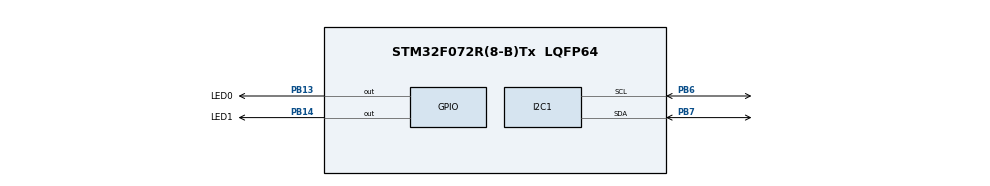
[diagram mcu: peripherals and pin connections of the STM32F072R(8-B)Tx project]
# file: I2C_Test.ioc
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Mcu.Family=STM32F0
Mcu.Name=STM32F072R(8-B)Tx
Mcu.Package=LQFP64
PB13.GPIO_Label=LED0
PB13.Signal=GPIO_Output
PB14.GPIO_Label=LED1
PB14.Signal=GPIO_Output
PB6.Mode=I2C
PB6.Signal=I2C1_SCL
PB7.Mode=I2C
PB7.Signal=I2C1_SDA
ProjectManager.HeapSize=0x200
ProjectManager.StackSize=0x400
ProjectManager.TargetToolchain=TrueSTUDIO
board=custom

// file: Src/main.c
/* USER CODE BEGIN Header */
/**
  ******************************************************************************
  * @file           : main.c
  * @brief          : Main program body
  ******************************************************************************
  * @attention
  *
  * <h2><center>&copy; Copyright (c) 2019 STMicroelectronics.
  * All rights reserved.</center></h2>
  *
  * This software component is licensed by ST under BSD 3-Clause license,
  * the "License"; You may not use this file except in compliance with the
  * License. You may obtain a copy of the License at:
  *                        opensource.org/licenses/BSD-3-Clause
  *
  ******************************************************************************
  */
/* USER CODE END Header */

#include "main.h"

/* USER CODE BEGIN Includes */
#include "pca9685.h"
#include "AFE.h"
/* USER CODE END Includes */

I2C_HandleTypeDef hi2c1;

void SystemClock_Config(void);
static void MX_GPIO_Init(void);
static void MX_I2C1_Init(void);

int main(void)
{

  /* MCU Configuration--------------------------------------------------------*/

  /* Reset of all peripherals, Initializes the Flash interface and the Systick. */
  HAL_Init();

  /* Configure the system clock */
  SystemClock_Config();

  /* Initialize all configured peripherals */
  MX_GPIO_Init();
  MX_I2C1_Init();
  /* USER CODE BEGIN 2 */

  pca_wake(&hi2c1);

  HAL_Delay(1000);
  pca_init(&hi2c1);
  pca_off(&hi2c1);
  HAL_GPIO_WritePin(LED0_GPIO_Port, LED0_Pin, GPIO_PIN_SET);

  HAL_Delay(1000);
  pca_write_color(&hi2c1, 0, WHITE);
  HAL_GPIO_WritePin(LED1_GPIO_Port, LED1_Pin, GPIO_PIN_SET);

  /* USER CODE END 2 */

  /* Infinite loop */
  /* USER CODE BEGIN WHILE */
  while (1)
  {
	  RGB cDrive = {0, 0, 4096};
    /* USER CODE END WHILE */
	  for(int i = 0; i < 4097; i+=16) {
		  cDrive.r = i;
		  for (uint8_t j = 0; j < 5; j++) {
			  pca_write_color(&hi2c1, j, cDrive);
			  HAL_Delay(1);
		  }
	  }

	  for(int i = 4096; i >= 0; i-=16) {
	  	  cDrive.b = i;
	  	  for (uint8_t j = 0; j < 5; j++) {
	  		  pca_write_color(&hi2c1, j, cDrive);
	  		  HAL_Delay(1);
	  	  }
	  }

	  for(int i = 0; i < 4097; i+=16) {
		  cDrive.g = i;
  		  for (uint8_t j = 0; j < 5; j++) {
  			  pca_write_color(&hi2c1, j, cDrive);
  			  HAL_Delay(1);
  		  }
  	  }

  	  for(int i = 4096; i >= 0; i-=16) {
  	  	  cDrive.r = i;
  	  	  for (uint8_t j = 0; j < 5; j++) {
  	  		  pca_write_color(&hi2c1, j, cDrive);
  	  		  HAL_Delay(1);
  	  	  }
  	  }

  	for(int i = 0; i < 4097; i+=16) {
		  cDrive.b = i;
  		  for (uint8_t j = 0; j < 5; j++) {
  			  pca_write_color(&hi2c1, j, cDrive);
  			  HAL_Delay(1);
  		  }
  	  }

  	  for(int i = 4096; i >= 0; i-=16) {
  	  	  cDrive.g = i;
  	  	  for (uint8_t j = 0; j < 5; j++) {
  	  		  pca_write_color(&hi2c1, j, cDrive);
  	  		  HAL_Delay(1);
  	  	  }
  	  }

  }
}

void SystemClock_Config(void)
{
  RCC_OscInitTypeDef RCC_OscInitStruct = {0};
  RCC_ClkInitTypeDef RCC_ClkInitStruct = {0};
  RCC_PeriphCLKInitTypeDef PeriphClkInit = {0};

  /** Initializes the CPU, AHB and APB busses clocks
  */
  RCC_OscInitStruct.OscillatorType = RCC_OSCILLATORTYPE_HSI;
  RCC_OscInitStruct.HSIState = RCC_HSI_ON;
  RCC_OscInitStruct.HSICalibrationValue = RCC_HSICALIBRATION_DEFAULT;
  RCC_OscInitStruct.PLL.PLLState = RCC_PLL_NONE;
  if (HAL_RCC_OscConfig(&RCC_OscInitStruct) != HAL_OK)
  {
    Error_Handler();
  }
  /** Initializes the CPU, AHB and APB busses clocks
  */
  RCC_ClkInitStruct.ClockType = RCC_CLOCKTYPE_HCLK|RCC_CLOCKTYPE_SYSCLK
                              |RCC_CLOCKTYPE_PCLK1;
  RCC_ClkInitStruct.SYSCLKSource = RCC_SYSCLKSOURCE_HSI;
  RCC_ClkInitStruct.AHBCLKDivider = RCC_SYSCLK_DIV1;
  RCC_ClkInitStruct.APB1CLKDivider = RCC_HCLK_DIV1;

  if (HAL_RCC_ClockConfig(&RCC_ClkInitStruct, FLASH_LATENCY_0) != HAL_OK)
  {
    Error_Handler();
  }
  PeriphClkInit.PeriphClockSelection = RCC_PERIPHCLK_I2C1;
  PeriphClkInit.I2c1ClockSelection = RCC_I2C1CLKSOURCE_HSI;
  if (HAL_RCCEx_PeriphCLKConfig(&PeriphClkInit) != HAL_OK)
  {
    Error_Handler();
  }
}

static void MX_I2C1_Init(void)
{

  hi2c1.Instance = I2C1;
  hi2c1.Init.Timing = 0x2000090E;
  hi2c1.Init.OwnAddress1 = 0;
  hi2c1.Init.AddressingMode = I2C_ADDRESSINGMODE_7BIT;
  hi2c1.Init.DualAddressMode = I2C_DUALADDRESS_DISABLE;
  hi2c1.Init.OwnAddress2 = 0;
  hi2c1.Init.OwnAddress2Masks = I2C_OA2_NOMASK;
  hi2c1.Init.GeneralCallMode = I2C_GENERALCALL_DISABLE;
  hi2c1.Init.NoStretchMode = I2C_NOSTRETCH_DISABLE;
  if (HAL_I2C_Init(&hi2c1) != HAL_OK)
  {
    Error_Handler();
  }
  /** Configure Analogue filter
  */
  if (HAL_I2CEx_ConfigAnalogFilter(&hi2c1, I2C_ANALOGFILTER_ENABLE) != HAL_OK)
  {
    Error_Handler();
  }
  /** Configure Digital filter
  */
  if (HAL_I2CEx_ConfigDigitalFilter(&hi2c1, 0) != HAL_OK)
  {
    Error_Handler();
  }

}

static void MX_GPIO_Init(void)
{
  GPIO_InitTypeDef GPIO_InitStruct = {0};

  /* GPIO Ports Clock Enable */
  __HAL_RCC_GPIOB_CLK_ENABLE();

  /*Configure GPIO pin Output Level */
  HAL_GPIO_WritePin(GPIOB, LED0_Pin|LED1_Pin, GPIO_PIN_RESET);

  /*Configure GPIO pins : LED0_Pin LED1_Pin */
  GPIO_InitStruct.Pin = LED0_Pin|LED1_Pin;
  GPIO_InitStruct.Mode = GPIO_MODE_OUTPUT_PP;
  GPIO_InitStruct.Pull = GPIO_NOPULL;
  GPIO_InitStruct.Speed = GPIO_SPEED_FREQ_LOW;
  HAL_GPIO_Init(GPIOB, &GPIO_InitStruct);

}

void Error_Handler(void)
{
}

/************************ (C) COPYRIGHT STMicroelectronics *****END OF FILE****/
